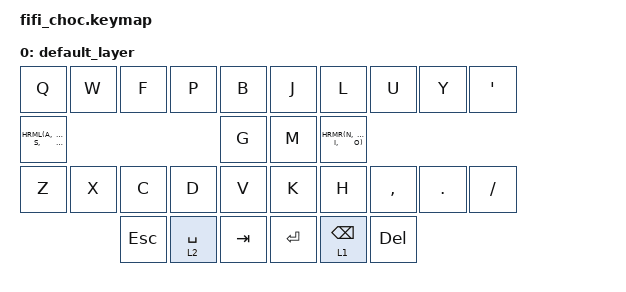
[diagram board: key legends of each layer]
// Copyright (c) 2024 Ray Cheng
// SPDX-License-Identifier: MIT

#include <behaviors.dtsi>
#include <dt-bindings/zmk/keys.h>
#include <dt-bindings/zmk/bt.h>

// Home row mods macro
#define HRML(k1,k2,k3,k4) &ht LGUI k1  &ht LALT k2  &ht LCTRL k3  &ht LSHFT k4
#define HRMR(k1,k2,k3,k4) &ht RSHIFT k1  &ht RCTRL k2  &ht RALT k3  &ht RGUI k4

/ {
    behaviors {
        ht: hold_tap {
            compatible = "zmk,behavior-hold-tap";
            #binding-cells = <2>;
            flavor = "tap-preferred";
            tapping-term-ms = <220>;
            quick-tap-ms = <150>;
            require-prior-idle-ms = <100>;
            bindings = <&kp>, <&kp>;
        };
    };

    conditional_layers {
        compatible = "zmk,conditional-layers";
    };

    keymap {
        compatible = "zmk,keymap";
        default_layer {
            bindings = <
        //╭──────────┬──────────┬──────────┬──────────┬──────────╮   ╭──────────┬──────────┬──────────┬──────────┬──────────╮
        //│  Q       │  W       │  F       │  P       │  B       │   │  J       │  L       │  U       │  Y       │ ' "      │
            &kp Q      &kp W      &kp F      &kp P      &kp B          &kp J      &kp L      &kp U      &kp Y      &kp SQT
        //├──────────┼──────────┼──────────┼──────────┼──────────┤   ├──────────┼──────────┼──────────┼──────────┼──────────┤
        //│  A       │  R       │  S       │  T       │  G       │   │  M       │  N       │  E       │  I       │ O        │
            HRML(A,        R,         S,         T)     &kp G          &kp M      HRMR(N,        E,         I,        O)
        //├──────────┼──────────┼──────────┼──────────┼──────────┤   ├──────────┼──────────┼──────────┼──────────┼──────────┤
        //│  Z       │  X       │  C       │  D       │  V       │   │  K       │  H       │ , <      │ . >      │ / ?      │
            &kp Z      &kp X      &kp C      &kp D      &kp V          &kp K      &kp H      &kp COMMA  &kp DOT    &kp FSLH
        //╰──────────┴──────────┼──────────┼──────────┼──────────┤   ├──────────┼──────────┼──────────┼──────────┴──────────╯
                                  &kp ESC   &lt 2 SPACE  &kp TAB      &kp ENTER  &lt 1 BSPC  &kp DEL
        //                      ╰──────────┴──────────┴──────────╯   ╰──────────┴──────────┴──────────╯
            >;
        };
    };
};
